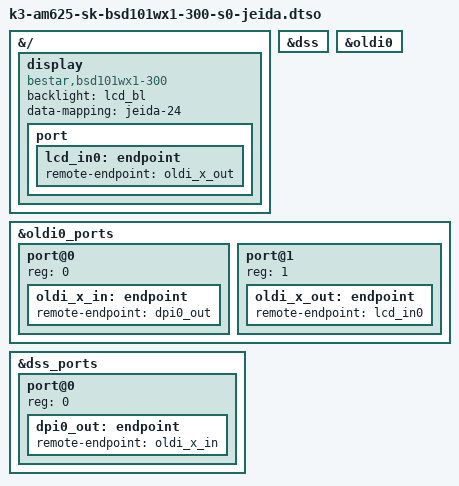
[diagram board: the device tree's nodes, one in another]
// SPDX-License-Identifier: GPL-2.0-or-later OR MIT
/* ===== CRZ TEMP bring-up variant for BSD101WX1-300: single-link OLDI0, JEIDA-24
 * Part of the LCD link/format test matrix. Select via uEnv.txt:
 *   dtbo_idx=0
 *   name_overlays=ti/k3-am625-sk-bsd101wx1-300-s0-jeida.dtbo
 * Remove unused variants once the working combination is known. ===== */
/dts-v1/;
/plugin/;

&{/} {
	display {
		compatible = "bestar,bsd101wx1-300", "panel-simple";
		backlight = <&lcd_bl>;
		data-mapping = "jeida-24";

		port {
			lcd_in0: endpoint {
				remote-endpoint = <&oldi_x_out>;
			};
		};
	};
};

&dss {
	status = "okay";
};

&oldi0 {
	status = "okay";
};

&oldi0_ports {
	#address-cells = <1>;
	#size-cells = <0>;

	port@0 {
		reg = <0>;
		oldi_x_in: endpoint {
			remote-endpoint = <&dpi0_out>;
		};
	};

	port@1 {
		reg = <1>;
		oldi_x_out: endpoint {
			remote-endpoint = <&lcd_in0>;
		};
	};
};

&dss_ports {
	#address-cells = <1>;
	#size-cells = <0>;

	port@0 {
		reg = <0>;
		dpi0_out: endpoint {
			remote-endpoint = <&oldi_x_in>;
		};
	};
};
